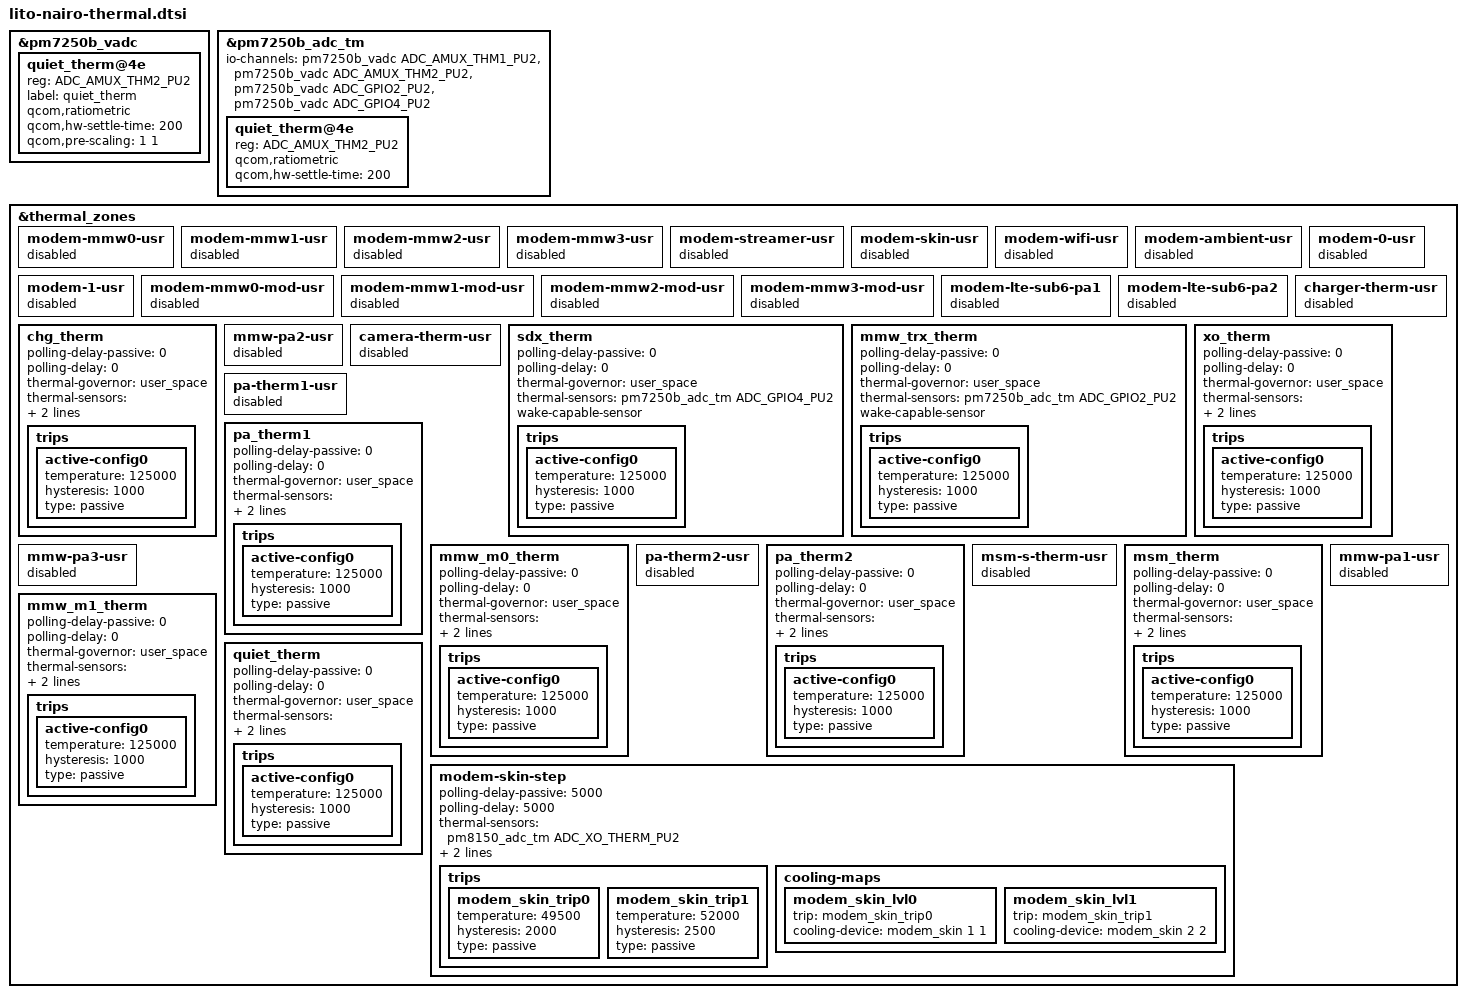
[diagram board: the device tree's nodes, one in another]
#include "moto_therm_sys_temp.dtsi"

&pm7250b_vadc {
	quiet_therm@4e {
		reg = <ADC_AMUX_THM2_PU2>;
		label = "quiet_therm";
		qcom,ratiometric;
		qcom,hw-settle-time = <200>;
		qcom,pre-scaling = <1 1>;
	};
};

&pm7250b_adc_tm {
	/delete-property/ io-channels;
	io-channels = <&pm7250b_vadc ADC_AMUX_THM1_PU2>,
			<&pm7250b_vadc ADC_AMUX_THM2_PU2>,
			<&pm7250b_vadc ADC_GPIO2_PU2>,
			<&pm7250b_vadc ADC_GPIO4_PU2>;

	quiet_therm@4e {
		reg = <ADC_AMUX_THM2_PU2>;
		qcom,ratiometric;
		qcom,hw-settle-time = <200>;
	};
};

&thermal_zones {
	/* Don't support sensors in 80-pj360-35_d */
	modem-mmw0-usr {
		status = "disabled";
	};
	modem-mmw1-usr {
		status = "disabled";
	};
	modem-mmw2-usr {
		status = "disabled";
	};
	modem-mmw3-usr {
		status = "disabled";
	};
	modem-streamer-usr {
		status = "disabled";
	};
	modem-skin-usr {
		status = "disabled";
	};
	modem-wifi-usr {
		status = "disabled";
	};
	modem-ambient-usr {
		status = "disabled";
	};
	modem-0-usr {
		status = "disabled";
	};
	modem-1-usr {
		status = "disabled";
	};
	modem-mmw0-mod-usr {
		status = "disabled";
	};
	modem-mmw1-mod-usr {
		status = "disabled";
	};
	modem-mmw2-mod-usr {
		status = "disabled";
	};
	modem-mmw3-mod-usr {
		status = "disabled";
	};

	/* equal to pa_therm1 */
	modem-lte-sub6-pa1 {
		status = "disabled";
	};
	/* equal to pa_therm2 */
	modem-lte-sub6-pa2 {
		status = "disabled";
	};

	charger-therm-usr {
		status = "disabled";
	};
	chg_therm {
		polling-delay-passive = <0>;
		polling-delay = <0>;
		thermal-governor = "user_space";
		thermal-sensors = <&pm7250b_adc_tm ADC_AMUX_THM1_PU2>;
		wake-capable-sensor;
		trips {
			active-config0 {
				temperature = <125000>;
				hysteresis = <1000>;
				type = "passive";
			};
		};
	};

	mmw-pa2-usr {
		status = "disabled";
	};

	camera-therm-usr {
		status = "disabled";
	};
	sdx_therm {
		polling-delay-passive = <0>;
		polling-delay = <0>;
		thermal-governor = "user_space";
		thermal-sensors = <&pm7250b_adc_tm ADC_GPIO4_PU2>;
		wake-capable-sensor;
		trips {
			active-config0 {
				temperature = <125000>;
				hysteresis = <1000>;
				type = "passive";
			};
		};
	};

	/* bmr_w_therm */
	mmw_trx_therm {
		polling-delay-passive = <0>;
		polling-delay = <0>;
		thermal-governor = "user_space";
		thermal-sensors = <&pm7250b_adc_tm ADC_GPIO2_PU2>;
		wake-capable-sensor;
		trips {
			active-config0 {
				temperature = <125000>;
				hysteresis = <1000>;
				type = "passive";
			};
		};
	};

	xo_therm {
		polling-delay-passive = <0>;
		polling-delay = <0>;
		thermal-governor = "user_space";
		thermal-sensors = <&pm8150_adc_tm ADC_XO_THERM_PU2>;
		wake-capable-sensor;
		trips {
			active-config0 {
				temperature = <125000>;
				hysteresis = <1000>;
				type = "passive";
			};
		};
	};

	pa-therm1-usr {
		status = "disabled";
	};
	pa_therm1 {
		polling-delay-passive = <0>;
		polling-delay = <0>;
		thermal-governor = "user_space";
		thermal-sensors = <&pm8150_adc_tm ADC_AMUX_THM1_PU2>;
		wake-capable-sensor;
		trips {
			active-config0 {
				temperature = <125000>;
				hysteresis = <1000>;
				type = "passive";
			};
		};
	};

	mmw-pa3-usr {
		status = "disabled";
	};
	/* bmr_e_therm */
	mmw_m0_therm {
		polling-delay-passive = <0>;
		polling-delay = <0>;
		thermal-governor = "user_space";
		thermal-sensors = <&pm8150_adc_tm ADC_AMUX_THM2_PU2>;
		wake-capable-sensor;
		trips {
			active-config0 {
				temperature = <125000>;
				hysteresis = <1000>;
				type = "passive";
			};
		};
	};

	pa-therm2-usr {
		status = "disabled";
	};
	pa_therm2 {
		polling-delay-passive = <0>;
		polling-delay = <0>;
		thermal-governor = "user_space";
		thermal-sensors = <&pm8150l_adc_tm ADC_AMUX_THM1_PU2>;
		wake-capable-sensor;
		trips {
			active-config0 {
				temperature = <125000>;
				hysteresis = <1000>;
				type = "passive";
			};
		};
	};

	msm-s-therm-usr {
		status = "disabled";
	};
	msm_therm {
		polling-delay-passive = <0>;
		polling-delay = <0>;
		thermal-governor = "user_space";
		thermal-sensors = <&pm8150l_adc_tm ADC_AMUX_THM2_PU2>;
		wake-capable-sensor;
		trips {
			active-config0 {
				temperature = <125000>;
				hysteresis = <1000>;
				type = "passive";
			};
		};
	};

	mmw-pa1-usr {
		status = "disabled";
	};
	/* bmr_n_therm */
	mmw_m1_therm {
		polling-delay-passive = <0>;
		polling-delay = <0>;
		thermal-governor = "user_space";
		thermal-sensors = <&pm8150l_adc_tm ADC_AMUX_THM3_PU2>;
		wake-capable-sensor;
		trips {
			active-config0 {
				temperature = <125000>;
				hysteresis = <1000>;
				type = "passive";
			};
		};
	};

	quiet_therm {
		polling-delay-passive = <0>;
		polling-delay = <0>;
		thermal-governor = "user_space";
		thermal-sensors = <&pm7250b_adc_tm ADC_AMUX_THM2_PU2>;
		wake-capable-sensor;
		trips {
			active-config0 {
				temperature = <125000>;
				hysteresis = <1000>;
				type = "passive";
			};
		};
	};

	modem-skin-step {
		polling-delay-passive = <5000>;
		polling-delay = <5000>;
		thermal-sensors = <&pm8150_adc_tm ADC_XO_THERM_PU2>;
		thermal-governor = "step_wise";
		wake-capable-sensor;
		trips {
			modem_skin_trip0: modem_skin_trip0 {
				temperature = <49500>;
				hysteresis = <2000>;
				type = "passive";
			};
			modem_skin_trip1: modem_skin_trip1 {
				temperature = <52000>;
				hysteresis = <2500>;
				type = "passive";
			};
		};
		cooling-maps {
			modem_skin_lvl0 {
				trip = <&modem_skin_trip0>;
				cooling-device = <&modem_skin 1 1>;
			};
			modem_skin_lvl1 {
				trip = <&modem_skin_trip1>;
				cooling-device = <&modem_skin 2 2>;
			};
		};
	};
};

